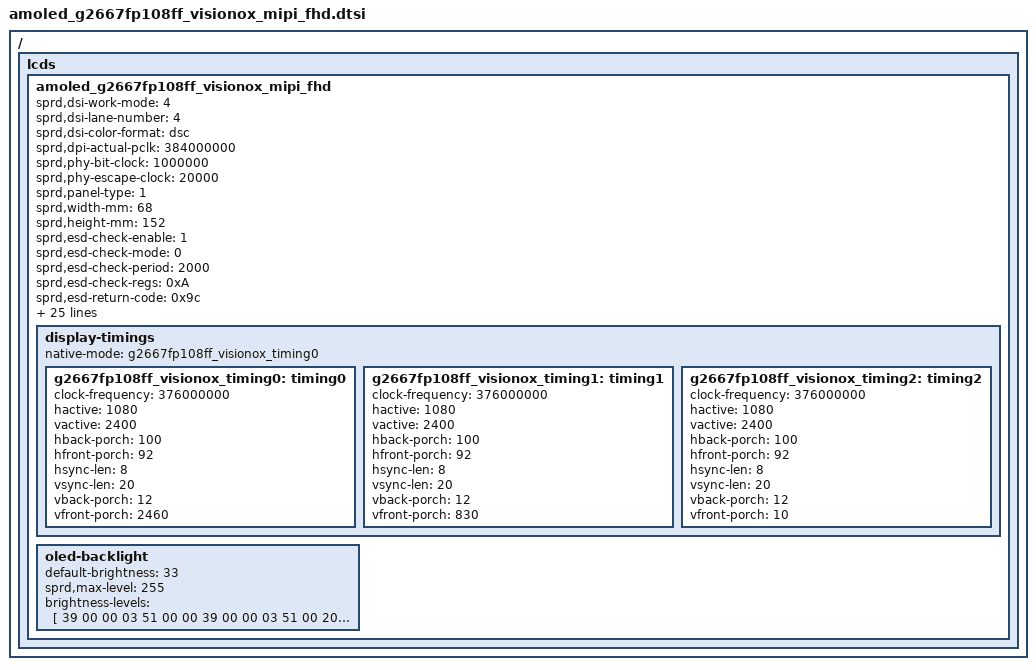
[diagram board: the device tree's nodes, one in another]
// SPDX-License-Identifier: GPL-2.0-only
/*
 * G2667 VISIONOX AMOLED config dtsi file for spreadtrum
 *
 * Copyright (C) 2021, Spreadtrum Communications Inc.
 */
/ {
	fragment {
		target-path = "/";
		__overlay__ {
			lcds {
				amoled_g2667fp108ff_visionox_mipi_fhd: amoled_g2667fp108ff_visionox_mipi_fhd {

					sprd,dsi-work-mode = <4>; /* cmd panel dpu run dpi mode*/
					sprd,dsi-lane-number = <4>;
					sprd,dsi-color-format = "dsc";
					sprd,dpi-actual-pclk = <384000000>;
					sprd,phy-bit-clock = <1000000>;	/* kbps */
					sprd,phy-escape-clock = <20000>;/* kHz */
					sprd,panel-type = <1>;

					sprd,width-mm = <68>;
					sprd,height-mm = <152>;

					sprd,esd-check-enable = <1>;
					sprd,esd-check-mode = <0>;
					sprd,esd-check-period = <2000>;
					sprd,esd-check-regs = <0xA>;
					sprd,esd-return-code = <0x9c>;

					sprd,slice-width = <540>;
					sprd,slice-height = <20>;
					sprd,output-bpc = <8>;
					sprd,dsc-enable = <1>;
					sprd,dual-dsi-enable = <0>;

					/* vrr config parameters */
					sprd,vrr-enabled;
					sprd,vrr-max-layers = <2>;
					sprd,supported-vrefresh-count = <3>;
					sprd,supported-vrefresh-rate = <120 90 60>;

					sprd,bl-prefix = [
						15 00 00 02 fe 00
					];

					sprd,vrefresh-cmd-120 = [
						15 00 00 02 fe 40
						15 00 00 02 bd 06
					];

					sprd,vrefresh-cmd-90 = [
						15 00 00 02 fe 40
						15 00 00 02 bd 05
					];

					sprd,vrefresh-cmd-60 = [
						15 00 00 02 fe 40
						15 00 00 02 bd 00
					];

					sprd,reset-on-sequence = <1 5>, <0 5>, <1 20>;
					sprd,reset-off-sequence = <0 5>;

					sprd,use-dcs-write;
					sprd,initial-command = [
						15 00 00 02 fe 40
						15 00 00 02 bd 00

						15 00 00 02 fe D2
						15 00 00 02 4f 08
						15 00 00 02 50 11
						15 00 00 02 51 89
						15 00 00 02 52 30
						15 00 00 02 53 09
						15 00 00 02 54 60
						15 00 00 02 55 04
						15 00 00 02 56 38
						15 00 00 02 58 00
						15 00 00 02 59 14
						15 00 00 02 5a 02
						15 00 00 02 5b 1c
						15 00 00 02 5d 00
						15 00 00 02 5e 20
						15 00 00 02 5f 01
						15 00 00 02 60 e8
						15 00 00 02 61 00
						15 00 00 02 62 07
						15 00 00 02 63 0c
						15 00 00 02 64 05
						15 00 00 02 65 0e
						15 00 00 02 66 05
						15 00 00 02 67 16
						15 00 00 02 68 18
						15 00 00 02 69 00
						15 00 00 02 6a 10
						15 00 00 02 6b f0
						15 00 00 02 6c 03
						15 00 00 02 6d 0c
						15 00 00 02 6e 20
						15 00 00 02 6f 00
						15 00 00 02 70 06
						15 00 00 02 71 0b
						15 00 00 02 72 0b
						15 00 00 02 73 33
						15 00 00 02 74 0e
						15 00 00 02 75 1c
						15 00 00 02 76 2a
						15 00 00 02 77 38
						15 00 00 02 78 46
						15 00 00 02 79 54
						15 00 00 02 7a 62
						15 00 00 02 7b 69
						15 00 00 02 7c 70
						15 00 00 02 7d 77
						15 00 00 02 7e 79
						15 00 00 02 7f 7b
						15 00 00 02 80 7d
						15 00 00 02 81 7e
						15 00 00 02 82 01
						15 00 00 02 83 02
						15 00 00 02 84 01
						15 00 00 02 85 00
						15 00 00 02 86 09
						15 00 00 02 87 40
						15 00 00 02 88 09
						15 00 00 02 89 be
						15 00 00 02 8a 19
						15 00 00 02 8b fc
						15 00 00 02 8d fa
						15 00 00 02 8e 19
						15 00 00 02 8f f8
						15 00 00 02 90 1a
						15 00 00 02 91 38
						15 00 00 02 92 1a
						15 00 00 02 93 78
						15 00 00 02 94 1a
						15 00 00 02 95 b6
						15 00 00 02 96 2a
						15 00 00 02 97 f6
						15 00 00 02 98 2b
						15 00 00 02 99 34
						15 00 00 02 9a 2b
						15 00 00 02 9b 74
						15 00 00 02 9c 3b
						15 00 00 02 9d 74
						15 00 00 02 9e 6b
						15 00 00 02 9f f4
						15 00 00 02 a2 02
						15 00 00 02 a3 1c
						15 00 00 02 a4 00
						15 00 00 02 a5 00
						15 00 00 02 a6 00
						15 00 00 02 a7 00
						15 00 00 02 a9 00
						15 00 00 02 aa 00
						15 00 00 02 a0 80
						15 00 00 02 fe 00
						39 00 00 03 44 04 b0
						15 00 00 02 fa 01
						15 00 00 02 c2 08
						15 00 00 02 35 00
						39 00 00 03 51 0d bb
						05 96 00 01 11
						05 32 00 01 29
						];

					sprd,sleep-in-command = [
						05 32 00 01 28
						05 32 00 01 10
						];

					sprd,sleep-out-command = [
						05 32 00 01 11
						05 32 00 01 29
						];

					display-timings {
						native-mode = <&g2667fp108ff_visionox_timing0>;

						g2667fp108ff_visionox_timing0: timing0 {
							clock-frequency = <376000000>;
							hactive = <1080>;
							vactive = <2400>;
							hback-porch = <100>;
							hfront-porch = <92>;
							hsync-len = <8>;
							vsync-len = <20>;
							vback-porch = <12>;
							vfront-porch = <2460>;
						};

						g2667fp108ff_visionox_timing1: timing1 {
							clock-frequency = <376000000>;
							hactive = <1080>;
							vactive = <2400>;
							hback-porch = <100>;
							hfront-porch = <92>;
							hsync-len = <8>;
							vsync-len = <20>;
							vback-porch = <12>;
							vfront-porch = <830>;
						};

						g2667fp108ff_visionox_timing2: timing2 {
							clock-frequency = <376000000>;
							hactive = <1080>;
							vactive = <2400>;
							hback-porch = <100>;
							hfront-porch = <92>;
							hsync-len = <8>;
							vsync-len = <20>;
							vback-porch = <12>;
							vfront-porch = <10>;
						};
					};

					oled-backlight {
						default-brightness = <33>;
						sprd,max-level = <255>;
						brightness-levels = [
							39 00 00 03 51 00 00
							39 00 00 03 51 00 20
							39 00 00 03 51 00 30
							39 00 00 03 51 00 40
							39 00 00 03 51 00 50
							39 00 00 03 51 00 60
							39 00 00 03 51 00 70
							39 00 00 03 51 00 80
							39 00 00 03 51 00 90
							39 00 00 03 51 00 A0
							39 00 00 03 51 00 B0
							39 00 00 03 51 00 C0
							39 00 00 03 51 00 D0
							39 00 00 03 51 00 E0
							39 00 00 03 51 00 F0
							39 00 00 03 51 01 00
							39 00 00 03 51 01 11
							39 00 00 03 51 01 21
							39 00 00 03 51 01 31
							39 00 00 03 51 01 41
							39 00 00 03 51 01 51
							39 00 00 03 51 01 61
							39 00 00 03 51 01 71
							39 00 00 03 51 01 81
							39 00 00 03 51 01 91
							39 00 00 03 51 01 A1
							39 00 00 03 51 01 B1
							39 00 00 03 51 01 C1
							39 00 00 03 51 01 D1
							39 00 00 03 51 01 E1
							39 00 00 03 51 01 F1
							39 00 00 03 51 02 01
							39 00 00 03 51 02 11
							39 00 00 03 51 02 22
							39 00 00 03 51 02 32
							39 00 00 03 51 02 42
							39 00 00 03 51 02 52
							39 00 00 03 51 02 62
							39 00 00 03 51 02 72
							39 00 00 03 51 02 82
							39 00 00 03 51 02 92
							39 00 00 03 51 02 A2
							39 00 00 03 51 02 B2
							39 00 00 03 51 02 C2
							39 00 00 03 51 02 D2
							39 00 00 03 51 02 E2
							39 00 00 03 51 02 F2
							39 00 00 03 51 03 02
							39 00 00 03 51 03 12
							39 00 00 03 51 03 22
							39 00 00 03 51 03 32
							39 00 00 03 51 03 43
							39 00 00 03 51 03 53
							39 00 00 03 51 03 63
							39 00 00 03 51 03 73
							39 00 00 03 51 03 83
							39 00 00 03 51 03 93
							39 00 00 03 51 03 A3
							39 00 00 03 51 03 B3
							39 00 00 03 51 03 C3
							39 00 00 03 51 03 D3
							39 00 00 03 51 03 E3
							39 00 00 03 51 03 F3
							39 00 00 03 51 04 03
							39 00 00 03 51 04 13
							39 00 00 03 51 04 23
							39 00 00 03 51 04 33
							39 00 00 03 51 04 43
							39 00 00 03 51 04 54
							39 00 00 03 51 04 64
							39 00 00 03 51 04 74
							39 00 00 03 51 04 84
							39 00 00 03 51 04 94
							39 00 00 03 51 04 A4
							39 00 00 03 51 04 B4
							39 00 00 03 51 04 C4
							39 00 00 03 51 04 D4
							39 00 00 03 51 04 E4
							39 00 00 03 51 04 F4
							39 00 00 03 51 05 04
							39 00 00 03 51 05 14
							39 00 00 03 51 05 24
							39 00 00 03 51 05 34
							39 00 00 03 51 05 44
							39 00 00 03 51 05 54
							39 00 00 03 51 05 65
							39 00 00 03 51 05 75
							39 00 00 03 51 05 85
							39 00 00 03 51 05 95
							39 00 00 03 51 05 A5
							39 00 00 03 51 05 B5
							39 00 00 03 51 05 C5
							39 00 00 03 51 05 D5
							39 00 00 03 51 05 E5
							39 00 00 03 51 05 F5
							39 00 00 03 51 06 05
							39 00 00 03 51 06 15
							39 00 00 03 51 06 25
							39 00 00 03 51 06 35
							39 00 00 03 51 06 45
							39 00 00 03 51 06 55
							39 00 00 03 51 06 65
							39 00 00 03 51 06 76
							39 00 00 03 51 06 86
							39 00 00 03 51 06 96
							39 00 00 03 51 06 A6
							39 00 00 03 51 06 B6
							39 00 00 03 51 06 C6
							39 00 00 03 51 06 D6
							39 00 00 03 51 06 E6
							39 00 00 03 51 06 F6
							39 00 00 03 51 07 06
							39 00 00 03 51 07 16
							39 00 00 03 51 07 26
							39 00 00 03 51 07 36
							39 00 00 03 51 07 46
							39 00 00 03 51 07 56
							39 00 00 03 51 07 66
							39 00 00 03 51 07 76
							39 00 00 03 51 07 87
							39 00 00 03 51 07 97
							39 00 00 03 51 07 A7
							39 00 00 03 51 07 B7
							39 00 00 03 51 07 C7
							39 00 00 03 51 07 D7
							39 00 00 03 51 07 E7
							39 00 00 03 51 07 F7
							39 00 00 03 51 08 07
							39 00 00 03 51 08 17
							39 00 00 03 51 08 27
							39 00 00 03 51 08 37
							39 00 00 03 51 08 47
							39 00 00 03 51 08 57
							39 00 00 03 51 08 67
							39 00 00 03 51 08 77
							39 00 00 03 51 08 87
							39 00 00 03 51 08 98
							39 00 00 03 51 08 A8
							39 00 00 03 51 08 B8
							39 00 00 03 51 08 C8
							39 00 00 03 51 08 D8
							39 00 00 03 51 08 E8
							39 00 00 03 51 08 F8
							39 00 00 03 51 09 08
							39 00 00 03 51 09 18
							39 00 00 03 51 09 28
							39 00 00 03 51 09 38
							39 00 00 03 51 09 48
							39 00 00 03 51 09 58
							39 00 00 03 51 09 68
							39 00 00 03 51 09 78
							39 00 00 03 51 09 88
							39 00 00 03 51 09 98
							39 00 00 03 51 09 A9
							39 00 00 03 51 09 B9
							39 00 00 03 51 09 C9
							39 00 00 03 51 09 D9
							39 00 00 03 51 09 E9
							39 00 00 03 51 09 F9
							39 00 00 03 51 0A 09
							39 00 00 03 51 0A 19
							39 00 00 03 51 0A 29
							39 00 00 03 51 0A 39
							39 00 00 03 51 0A 49
							39 00 00 03 51 0A 59
							39 00 00 03 51 0A 69
							39 00 00 03 51 0A 79
							39 00 00 03 51 0A 89
							39 00 00 03 51 0A 99
							39 00 00 03 51 0A A9
							39 00 00 03 51 0A BA
							39 00 00 03 51 0A CA
							39 00 00 03 51 0A DA
							39 00 00 03 51 0A EA
							39 00 00 03 51 0A FA
							39 00 00 03 51 0B 0A
							39 00 00 03 51 0B 1A
							39 00 00 03 51 0B 2A
							39 00 00 03 51 0B 3A
							39 00 00 03 51 0B 4A
							39 00 00 03 51 0B 5A
							39 00 00 03 51 0B 6A
							39 00 00 03 51 0B 7A
							39 00 00 03 51 0B 8A
							39 00 00 03 51 0B 9A
							39 00 00 03 51 0B AA
							39 00 00 03 51 0B BA
							39 00 00 03 51 0B CB
							39 00 00 03 51 0B DB
							39 00 00 03 51 0B EB
							39 00 00 03 51 0B FB
							39 00 00 03 51 0C 0B
							39 00 00 03 51 0C 1B
							39 00 00 03 51 0C 2B
							39 00 00 03 51 0C 3B
							39 00 00 03 51 0C 4B
							39 00 00 03 51 0C 5B
							39 00 00 03 51 0C 6B
							39 00 00 03 51 0C 7B
							39 00 00 03 51 0C 8B
							39 00 00 03 51 0C 9B
							39 00 00 03 51 0C AB
							39 00 00 03 51 0C BB
							39 00 00 03 51 0C CB
							39 00 00 03 51 0C DC
							39 00 00 03 51 0C EC
							39 00 00 03 51 0C FC
							39 00 00 03 51 0D 0C
							39 00 00 03 51 0D 1C
							39 00 00 03 51 0D 2C
							39 00 00 03 51 0D 3C
							39 00 00 03 51 0D 4C
							39 00 00 03 51 0D 5C
							39 00 00 03 51 0D 6C
							39 00 00 03 51 0D 7C
							39 00 00 03 51 0D 8C
							39 00 00 03 51 0D 9C
							39 00 00 03 51 0D AC
							39 00 00 03 51 0D BC
							39 00 00 03 51 0D CC
							39 00 00 03 51 0D DC
							39 00 00 03 51 0D ED
							39 00 00 03 51 0D FD
							39 00 00 03 51 0E 0D
							39 00 00 03 51 0E 1D
							39 00 00 03 51 0E 2D
							39 00 00 03 51 0E 3D
							39 00 00 03 51 0E 4D
							39 00 00 03 51 0E 5D
							39 00 00 03 51 0E 6D
							39 00 00 03 51 0E 7D
							39 00 00 03 51 0E 8D
							39 00 00 03 51 0E 9D
							39 00 00 03 51 0E AD
							39 00 00 03 51 0E BD
							39 00 00 03 51 0E CD
							39 00 00 03 51 0E DD
							39 00 00 03 51 0E ED
							39 00 00 03 51 0E FE
							39 00 00 03 51 0F 0E
							39 00 00 03 51 0F 1E
							39 00 00 03 51 0F 2E
							39 00 00 03 51 0F 3E
							39 00 00 03 51 0F 4E
							39 00 00 03 51 0F 5E
							39 00 00 03 51 0F 6E
							39 00 00 03 51 0F 7E
							39 00 00 03 51 0F 8E
							39 00 00 03 51 0F 9E
							39 00 00 03 51 0F AE
							39 00 00 03 51 0F BE
							39 00 00 03 51 0F CE
							39 00 00 03 51 0F DE
							39 00 00 03 51 0F EE
							39 00 00 03 51 0F FE
							39 00 00 03 51 0F FE
						];
					};
				};
			};
		};
	};
};
